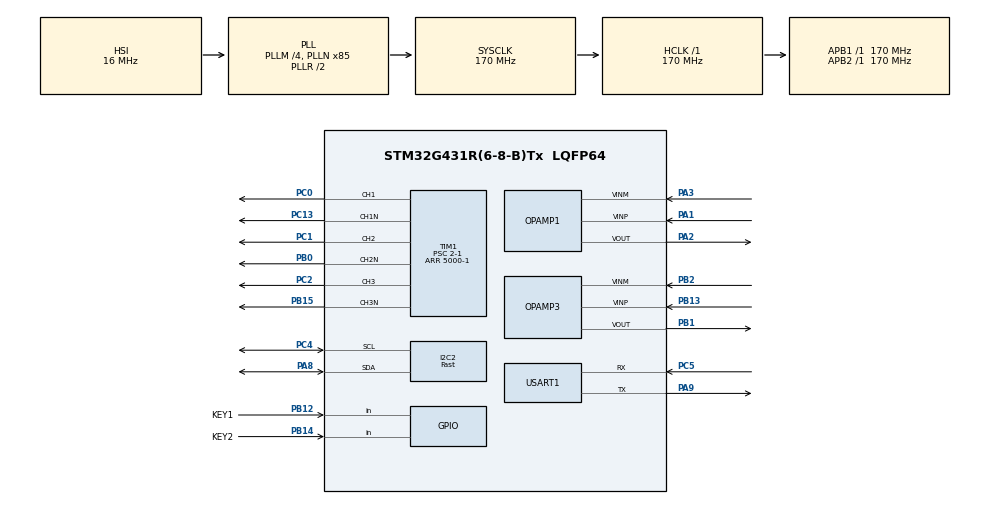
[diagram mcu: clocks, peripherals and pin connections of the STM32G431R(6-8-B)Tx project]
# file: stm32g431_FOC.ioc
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ADC1.ContinuousConvMode=DISABLE
ADC1.DMAContinuousRequests=DISABLE
ADC1.EOCSelection=ADC_EOC_SEQ_CONV
ADC1.EnableInjectedConversion=ENABLE
ADC1.EnableRegularConversion=DISABLE
ADC1.ExternalTrigInjecConv=ADC_EXTERNALTRIGINJEC_T1_TRGO
ADC1.ExternalTrigInjecConvEdge=ADC_EXTERNALTRIGINJECCONV_EDGE_FALLING
ADC1.InjNumberOfConversion=2
ADC1.InjectedChannel-5\#ChannelInjectedConversion=ADC_CHANNEL_3
ADC1.InjectedChannel-6\#ChannelInjectedConversion=ADC_CHANNEL_12
ADC1.InjectedOffsetNumber-5\#ChannelInjectedConversion=ADC_OFFSET_NONE
ADC1.InjectedOffsetNumber-6\#ChannelInjectedConversion=ADC_OFFSET_NONE
ADC1.InjectedRank-5\#ChannelInjectedConversion=1
ADC1.InjectedRank-6\#ChannelInjectedConversion=2
ADC1.InjectedSamplingTime-5\#ChannelInjectedConversion=ADC_SAMPLETIME_6CYCLES_5
ADC1.InjectedSamplingTime-6\#ChannelInjectedConversion=ADC_SAMPLETIME_6CYCLES_5
ADC1.master=1
Dma.Request0=USART1_RX
Dma.Request1=USART1_TX
Dma.USART1_RX.0.Direction=DMA_PERIPH_TO_MEMORY
Dma.USART1_RX.0.EventEnable=DISABLE
Dma.USART1_RX.0.Instance=DMA1_Channel1
Dma.USART1_RX.0.MemDataAlignment=DMA_MDATAALIGN_BYTE
Dma.USART1_RX.0.MemInc=DMA_MINC_ENABLE
Dma.USART1_RX.0.Mode=DMA_NORMAL
Dma.USART1_RX.0.PeriphDataAlignment=DMA_PDATAALIGN_BYTE
Dma.USART1_RX.0.PeriphInc=DMA_PINC_DISABLE
Dma.USART1_RX.0.Polarity=HAL_DMAMUX_REQ_GEN_RISING
Dma.USART1_RX.0.Priority=DMA_PRIORITY_LOW
Dma.USART1_RX.0.RequestNumber=1
Dma.USART1_RX.0.SignalID=NONE
Dma.USART1_RX.0.SyncEnable=DISABLE
Dma.USART1_RX.0.SyncPolarity=HAL_DMAMUX_SYNC_NO_EVENT
Dma.USART1_RX.0.SyncRequestNumber=1
Dma.USART1_RX.0.SyncSignalID=NONE
Dma.USART1_TX.1.Direction=DMA_MEMORY_TO_PERIPH
Dma.USART1_TX.1.EventEnable=DISABLE
Dma.USART1_TX.1.Instance=DMA1_Channel2
Dma.USART1_TX.1.MemDataAlignment=DMA_MDATAALIGN_BYTE
Dma.USART1_TX.1.MemInc=DMA_MINC_ENABLE
Dma.USART1_TX.1.Mode=DMA_NORMAL
Dma.USART1_TX.1.PeriphDataAlignment=DMA_PDATAALIGN_BYTE
Dma.USART1_TX.1.PeriphInc=DMA_PINC_DISABLE
Dma.USART1_TX.1.Polarity=HAL_DMAMUX_REQ_GEN_RISING
Dma.USART1_TX.1.Priority=DMA_PRIORITY_LOW
Dma.USART1_TX.1.RequestNumber=1
Dma.USART1_TX.1.SignalID=NONE
Dma.USART1_TX.1.SyncEnable=DISABLE
Dma.USART1_TX.1.SyncPolarity=HAL_DMAMUX_SYNC_NO_EVENT
Dma.USART1_TX.1.SyncRequestNumber=1
Dma.USART1_TX.1.SyncSignalID=NONE
I2C2.I2C_Speed_Mode=I2C_Fast
I2C2.Timing=0x40621236
Mcu.Family=STM32G4
Mcu.Name=STM32G431R(6-8-B)Tx
Mcu.Package=LQFP64
NVIC.ADC1_2_IRQn=true\:1\:0\:true\:false\:true\:true\:true\:true
NVIC.DMA1_Channel1_IRQn=true\:0\:0\:false\:false\:true\:false\:true\:true
NVIC.DMA1_Channel2_IRQn=true\:0\:0\:false\:false\:true\:false\:true\:true
NVIC.PriorityGroup=NVIC_PRIORITYGROUP_4
NVIC.USART1_IRQn=true\:0\:0\:false\:false\:true\:true\:true\:true
PA1.Mode=Standalone
PA1.Signal=OPAMP1_VINP
PA13.Mode=Serial_Wire
PA13.Signal=SYS_JTMS-SWDIO
PA14.Mode=Serial_Wire
PA14.Signal=SYS_JTCK-SWCLK
PA2.Signal=SharedAnalog_PA2
PA3.Mode=Standalone
PA3.Signal=OPAMP1_VINM
PA8.Mode=I2C
PA8.Signal=I2C2_SDA
PA9.Mode=Asynchronous
PA9.Signal=USART1_TX
PB0.GPIO_Speed=GPIO_SPEED_FREQ_LOW
PB0.Mode=PWM Generation2 CH2 CH2N
PB0.Signal=TIM1_CH2N
PB1.Signal=SharedAnalog_PB1
PB12.GPIO_Label=KEY1
PB12.GPIO_PuPd=GPIO_PULLUP
PB12.Signal=GPIO_Input
PB13.Mode=Standalone
PB13.Signal=OPAMP3_VINP
PB14.GPIO_Label=KEY2
PB14.GPIO_PuPd=GPIO_PULLUP
PB14.Signal=GPIO_Input
PB15.GPIO_Speed=GPIO_SPEED_FREQ_LOW
PB15.Mode=PWM Generation3 CH3 CH3N
PB15.Signal=TIM1_CH3N
PB2.Mode=Standalone
PB2.Signal=OPAMP3_VINM
PC0.GPIO_Speed=GPIO_SPEED_FREQ_LOW
PC0.Signal=S_TIM1_CH1
PC1.GPIO_Speed=GPIO_SPEED_FREQ_LOW
PC1.Signal=S_TIM1_CH2
PC13.GPIO_Speed=GPIO_SPEED_FREQ_LOW
PC13.Mode=PWM Generation1 CH1 CH1N
PC13.Signal=TIM1_CH1N
PC2.GPIO_Speed=GPIO_SPEED_FREQ_LOW
PC2.Signal=S_TIM1_CH3
PC4.Mode=I2C
PC4.Signal=I2C2_SCL
PC5.Mode=Asynchronous
PC5.Signal=USART1_RX
PF0-OSC_IN.Mode=HSE-External-Oscillator
PF0-OSC_IN.Signal=RCC_OSC_IN
PF1-OSC_OUT.Mode=HSE-External-Oscillator
PF1-OSC_OUT.Signal=RCC_OSC_OUT
ProjectManager.HeapSize=0x400
ProjectManager.StackSize=0x600
ProjectManager.TargetToolchain=MDK-ARM V5.32
RCC.ADC12Freq_Value=170000000
RCC.AHBFreq_Value=170000000
RCC.APB1Freq_Value=170000000
RCC.APB1TimFreq_Value=170000000
RCC.APB2Freq_Value=170000000
RCC.APB2TimFreq_Value=170000000
RCC.CortexFreq_Value=170000000
RCC.EXTERNAL_CLOCK_VALUE=12288000
RCC.HCLKFreq_Value=170000000
RCC.HSE_VALUE=8000000
RCC.HSI48_VALUE=48000000
RCC.HSI_VALUE=16000000
RCC.LSE_VALUE=32768
RCC.PLLM=RCC_PLLM_DIV4
RCC.PLLN=85
RCC.SYSCLKFreq_VALUE=170000000
RCC.SYSCLKSource=RCC_SYSCLKSOURCE_PLLCLK
RCC.USBFreq_Value=170000000
RCC.VCOOutputFreq_Value=340000000
SH.S_TIM1_CH1.0=TIM1_CH1,PWM Generation1 CH1 CH1N
SH.S_TIM1_CH2.0=TIM1_CH2,PWM Generation2 CH2 CH2N
SH.S_TIM1_CH3.0=TIM1_CH3,PWM Generation3 CH3 CH3N
SH.SharedAnalog_PA2.0=OPAMP1_VOUT,Standalone
SH.SharedAnalog_PA2.1=ADC1_IN3,IN3-Single-Ended
SH.SharedAnalog_PB1.0=OPAMP3_VOUT,Standalone
SH.SharedAnalog_PB1.1=ADC1_IN12,IN12-Single-Ended
TIM1.AutoReloadPreload=TIM_AUTORELOAD_PRELOAD_ENABLE
TIM1.BreakPolarity=TIM_BREAKPOLARITY_LOW
TIM1.Channel-PWM\ Generation1\ CH1\ CH1N=TIM_CHANNEL_1
TIM1.Channel-PWM\ Generation2\ CH2\ CH2N=TIM_CHANNEL_2
TIM1.Channel-PWM\ Generation3\ CH3\ CH3N=TIM_CHANNEL_3
TIM1.CounterMode=TIM_COUNTERMODE_CENTERALIGNED1
TIM1.DeadTime=100
TIM1.DeadTimePreload=DISABLE
TIM1.OCMode_PWM-PWM\ Generation1\ CH1\ CH1N=TIM_OCMODE_PWM2
TIM1.OCMode_PWM-PWM\ Generation2\ CH2\ CH2N=TIM_OCMODE_PWM2
TIM1.OCMode_PWM-PWM\ Generation3\ CH3\ CH3N=TIM_OCMODE_PWM2
TIM1.PeriodNoDither=5000-1
TIM1.Prescaler=2-1
TIM1.RepetitionCounter=1
TIM1.TIM_MasterOutputTrigger=TIM_TRGO_UPDATE
TIM7.PeriodNoDither=2000-1
TIM7.Prescaler=170-1
USART1.VirtualMode-Asynchronous=VM_ASYNC
VP_SYS_VS_DBSignals.Mode=DisableDeadBatterySignals
VP_TIM1_VS_ClockSourceINT.Mode=Internal
VP_TIM7_VS_ClockSourceINT.Mode=Enable_Timer
board=custom

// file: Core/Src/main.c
/* USER CODE BEGIN Header */
/**
  ******************************************************************************
  * @file           : main.c
  * @brief          : Main program body
  ******************************************************************************
  * @attention
  *
  * Copyright (c) 2025 STMicroelectronics.
  * All rights reserved.
  *
  * This software is licensed under terms that can be found in the LICENSE file
  * in the root directory of this software component.
  * If no LICENSE file comes with this software, it is provided AS-IS.
  *
  ******************************************************************************
  */
/* USER CODE END Header */
#include "main.h"
#include "adc.h"
#include "dma.h"
#include "i2c.h"
#include "opamp.h"
#include "tim.h"
#include "usart.h"
#include "gpio.h"

/* USER CODE BEGIN Includes */

#include "Headfile.h"

/* USER CODE END Includes */

void SystemClock_Config(void);

int main(void)
{

  /* MCU Configuration--------------------------------------------------------*/

  /* Reset of all peripherals, Initializes the Flash interface and the Systick. */
  HAL_Init();

  /* Configure the system clock */
  SystemClock_Config();

  /* Initialize all configured peripherals */
  MX_GPIO_Init();
  MX_DMA_Init();
  MX_ADC1_Init();
  MX_I2C2_Init();
  MX_OPAMP1_Init();
  MX_OPAMP3_Init();
  MX_TIM1_Init();
  MX_USART1_UART_Init();
  MX_TIM7_Init();
  /* USER CODE BEGIN 2 */

	mcu_module_init();    /* BSP外设初始化 */
	pid_init();           /* pid参数初始化 */
	motor_state_init();   /* 电机控制状态初始化 */
	vofa_test_init();     /* 下位机接收中断初始化 */

  /* USER CODE END 2 */

  /* Infinite loop */
  /* USER CODE BEGIN WHILE */
  while (1)
  {
      UART_RX_Handle();       /* 在空闲中断中接收完一次数据后，对其进行处理 */
			printf("%1.4f,%1.4f,%1.4f,%1.4f,%1.4f,%1.4f\n",Park_DQ.theta,Park_DQ.I_q,Park_DQ.I_d,Current_abc.Ia,Current_abc.Ib,Current_abc.Ic);    /* 上位机数据监测 */

    /* USER CODE END WHILE */

  }
}

void SystemClock_Config(void)
{
  RCC_OscInitTypeDef RCC_OscInitStruct = {0};
  RCC_ClkInitTypeDef RCC_ClkInitStruct = {0};

  /** Configure the main internal regulator output voltage
  */
  HAL_PWREx_ControlVoltageScaling(PWR_REGULATOR_VOLTAGE_SCALE1_BOOST);

  /** Initializes the RCC Oscillators according to the specified parameters
  * in the RCC_OscInitTypeDef structure.
  */
  RCC_OscInitStruct.OscillatorType = RCC_OSCILLATORTYPE_HSI;
  RCC_OscInitStruct.HSIState = RCC_HSI_ON;
  RCC_OscInitStruct.HSICalibrationValue = RCC_HSICALIBRATION_DEFAULT;
  RCC_OscInitStruct.PLL.PLLState = RCC_PLL_ON;
  RCC_OscInitStruct.PLL.PLLSource = RCC_PLLSOURCE_HSI;
  RCC_OscInitStruct.PLL.PLLM = RCC_PLLM_DIV4;
  RCC_OscInitStruct.PLL.PLLN = 85;
  RCC_OscInitStruct.PLL.PLLP = RCC_PLLP_DIV2;
  RCC_OscInitStruct.PLL.PLLQ = RCC_PLLQ_DIV2;
  RCC_OscInitStruct.PLL.PLLR = RCC_PLLR_DIV2;
  if (HAL_RCC_OscConfig(&RCC_OscInitStruct) != HAL_OK)
  {
    Error_Handler();
  }

  /** Initializes the CPU, AHB and APB buses clocks
  */
  RCC_ClkInitStruct.ClockType = RCC_CLOCKTYPE_HCLK|RCC_CLOCKTYPE_SYSCLK
                              |RCC_CLOCKTYPE_PCLK1|RCC_CLOCKTYPE_PCLK2;
  RCC_ClkInitStruct.SYSCLKSource = RCC_SYSCLKSOURCE_PLLCLK;
  RCC_ClkInitStruct.AHBCLKDivider = RCC_SYSCLK_DIV1;
  RCC_ClkInitStruct.APB1CLKDivider = RCC_HCLK_DIV1;
  RCC_ClkInitStruct.APB2CLKDivider = RCC_HCLK_DIV1;

  if (HAL_RCC_ClockConfig(&RCC_ClkInitStruct, FLASH_LATENCY_4) != HAL_OK)
  {
    Error_Handler();
  }
}

void Error_Handler(void)
{
  __disable_irq();
  while (1)
  {
  }
}
